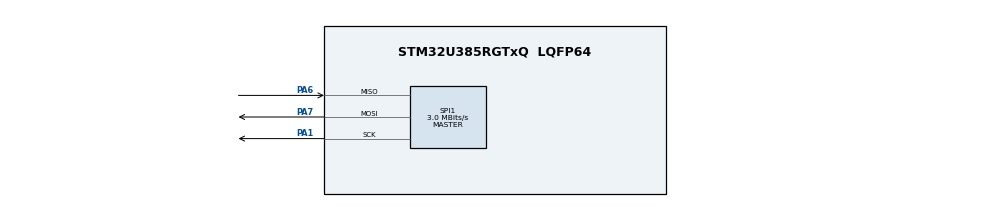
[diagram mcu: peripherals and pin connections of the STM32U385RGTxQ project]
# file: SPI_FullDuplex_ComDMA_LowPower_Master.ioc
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CORTEX_M33_NS.userName=CORTEX_M33
GPDMA1.DATAHANDLING_GPDMACH10=ENABLE
GPDMA1.DATAHANDLING_GPDMACH11=ENABLE
GPDMA1.DESTINC_GPDMACH11=DMA_DINC_INCREMENTED
GPDMA1.DIRECTION_GPDMACH10=DMA_MEMORY_TO_PERIPH
GPDMA1.IPHANDLE_GPDMACH10-SIMPLEREQUEST_GPDMACH10=__NULL
GPDMA1.IPHANDLE_GPDMACH11-SIMPLEREQUEST_GPDMACH11=__NULL
GPDMA1.REQUEST_GPDMACH10=GPDMA1_REQUEST_SPI1_TX
GPDMA1.REQUEST_GPDMACH11=GPDMA1_REQUEST_SPI1_RX
GPDMA1.SRCINC_GPDMACH10=DMA_SINC_INCREMENTED
Mcu.Family=STM32U3
Mcu.Name=STM32U385RGTxQ
Mcu.Package=LQFP64
NVIC.GPDMA1_Channel10_IRQn=true\:0\:0\:false\:false\:true\:false\:true\:true
NVIC.GPDMA1_Channel11_IRQn=true\:0\:0\:false\:false\:true\:false\:true\:true
NVIC.PriorityGroup=NVIC_PRIORITYGROUP_4
NVIC.SPI1_IRQn=true\:0\:0\:false\:false\:true\:false\:true\:true
PA1.GPIO_Speed=GPIO_SPEED_FREQ_HIGH
PA1.Mode=Full_Duplex_Master
PA1.Signal=SPI1_SCK
PA6.GPIO_Speed=GPIO_SPEED_FREQ_HIGH
PA6.Mode=Full_Duplex_Master
PA6.Signal=SPI1_MISO
PA7.GPIO_Speed=GPIO_SPEED_FREQ_HIGH
PA7.Mode=Full_Duplex_Master
PA7.Signal=SPI1_MOSI
PC14-OSC32_IN\ (PC14).Mode=LSE-External-Oscillator
PC14-OSC32_IN\ (PC14).Signal=RCC_OSC32_IN
PC15-OSC32_OUT\ (PC15).Mode=LSE-External-Oscillator
PC15-OSC32_OUT\ (PC15).Signal=RCC_OSC32_OUT
ProjectManager.HeapSize=0x200
ProjectManager.StackSize=0x400
ProjectManager.TargetToolchain=EWARM V9.20
RCC.ADCFreq_Value=24000000
RCC.AHBFreq_Value=24000000
RCC.APB1Freq_Value=24000000
RCC.APB1TimFreq_Value=24000000
RCC.APB2Freq_Value=24000000
RCC.APB2TimFreq_Value=24000000
RCC.APB3Freq_Value=24000000
RCC.CortexFreq_Value=3000000
RCC.HCLKFreq_Value=24000000
RCC.HSE_VALUE=16000000
RCC.HSI48_VALUE=48000000
RCC.HSI_VALUE=16000000
RCC.LSIDIV_VALUE=32000
RCC.MSIKSource=RCC_MSI_RC1
RCC.MSISDIV=RCC_MSI_DIV1
RCC.MSISSource=RCC_MSI_RC1
RCC.RTCClockSelection=RCC_RTCCLKSOURCE_LSE
RCC.SPI1CLockSelection=RCC_SPI1CLKSOURCE_MSIK
RCC.SYSCLKFreq_VALUE=24000000
RCC.USBFreq_Value=24000000
RTC.WakeUpCounter-WakeUp=10240
SPI1.BaudRatePrescaler=SPI_BAUDRATEPRESCALER_8
SPI1.CalculateBaudRate=3.0 MBits/s
SPI1.DataSize=SPI_DATASIZE_8BIT
SPI1.Direction=SPI_DIRECTION_2LINES
SPI1.Mode=SPI_MODE_MASTER
SPI1.TriggerSelection=SPI_GRP1_RTC_WUT_TRG
SPI1.TriggerState=SPI_AUTO_MODE_ENABLE
SPI1.VirtualType=VM_MASTER
VP_GPDMA1_VS_GPDMACH10.Mode=SIMPLEREQUEST_GPDMACH10
VP_GPDMA1_VS_GPDMACH11.Mode=SIMPLEREQUEST_GPDMACH11
VP_ICACHE_VS_ICACHE.Mode=DirectMappedCache
VP_PWR_VS_DBSignals.Mode=DisableDeadBatterySignals
VP_PWR_VS_LPOM.Mode=PowerOptimisation
VP_PWR_VS_SECSignals.Mode=Security/Privilege
VP_RTC_VS_RTC_Activate.Mode=RTC_Enabled
VP_RTC_VS_RTC_WakeUp_intern.Mode=WakeUp
board=custom

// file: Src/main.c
/* USER CODE BEGIN Header */
/**
  ******************************************************************************
  * @file           : main.c
  * @brief          : Main program body
  ******************************************************************************
  * @attention
  *
  * Copyright (c) 2024 STMicroelectronics.
  * All rights reserved.
  *
  * This software is licensed under terms that can be found in the LICENSE file
  * in the root directory of this software component.
  * If no LICENSE file comes with this software, it is provided AS-IS.
  *
  ******************************************************************************
  */
/* USER CODE END Header */
#include "main.h"

/* USER CODE BEGIN PTD */
enum {
	TRANSFER_WAIT,
	TRANSFER_COMPLETE,
	TRANSFER_ERROR
};
/* USER CODE END PTD */

/* USER CODE BEGIN PD */
uint8_t aTxBuffer[] = "****SPI - Two Boards communication based on DMA **** SPI Message ******** SPI Message ******** SPI Message ****";

/* Buffer used for reception */
#define BUFFER_ALIGNED_SIZE (((BUFFERSIZE+31)/32)*32)
ALIGN_32BYTES(uint8_t aRxBuffer[BUFFER_ALIGNED_SIZE]);

/* transfer state */
__IO uint32_t wTransferState = TRANSFER_WAIT;
/* USER CODE END PD */

RTC_HandleTypeDef hrtc;

SPI_HandleTypeDef hspi1;
DMA_HandleTypeDef handle_GPDMA1_Channel11;
DMA_HandleTypeDef handle_GPDMA1_Channel10;

void SystemClock_Config(void);
static void MX_GPIO_Init(void);
static void MX_GPDMA1_Init(void);
static void MX_SPI1_Init(void);
static void MX_ICACHE_Init(void);
static void MX_RTC_Init(void);
/* USER CODE BEGIN PFP */
static uint16_t Buffercmp(uint8_t *pBuffer1, uint8_t *pBuffer2, uint16_t BufferLength);
/* USER CODE END PFP */

int main(void)
{

  /* USER CODE BEGIN 1 */
  /* STM32U3xx HAL library initialization:
       - Configure the Flash prefetch
       - Configure the Systick to generate an interrupt each 1 msec
       - Set NVIC Group Priority to 3
       - Low Level Initialization
     */
  /* USER CODE END 1 */

  /* MCU Configuration--------------------------------------------------------*/

  /* Reset of all peripherals, Initializes the Flash interface and the Systick. */
  HAL_Init();

  /* Configure the system clock */
  SystemClock_Config();

  /* USER CODE BEGIN SysInit */
  /* Configure LED2 */
  BSP_LED_Init(LD2);

  /* USER CODE END SysInit */

  /* Initialize all configured peripherals */
  MX_GPIO_Init();
  MX_GPDMA1_Init();
  MX_SPI1_Init();
  MX_ICACHE_Init();
  MX_RTC_Init();
  /* USER CODE BEGIN 2 */

  __HAL_RTC_CLEAR_FLAG(hrtc, RTC_CLEAR_WUTF);

    /*##-2- Start the Full Duplex Communication process ########################*/
  /* While the SPI in TransmitReceive process, user can transmit data through
     "aTxBuffer" buffer & receive data through "aRxBuffer" */
  if(HAL_SPI_TransmitReceive_DMA(&hspi1, (uint8_t*)aTxBuffer, (uint8_t *)aRxBuffer, BUFFERSIZE) != HAL_OK)
  {
    /* Transfer error in transmission process */
    Error_Handler();
  }

  /* Disable debug to avoid some buses to stay awake */
  HAL_DBGMCU_DisableDBGStopMode();

  /* Suspend Tick increment */
  HAL_SuspendTick();

  /* Enter in low power mode(STOP1) and wait for the SPI end of transfer interrupt to be awoken.
    The DMA transfer is triggered by the RTC timer, the MCU is in low power mode during the RTC
    count down and during the DMA transfer */
  HAL_PWR_EnterSTOPMode(PWR_LOWPOWERMODE_STOP1, PWR_STOPENTRY_WFI);

  /* Resume Tick increment */
  HAL_ResumeTick();

  /*##-3- Wait for the end of the transfer ###################################*/
  /*  Before starting a new communication transfer, you must wait the callback call
      to get the transfer complete confirmation or an error detection. */
  while (wTransferState == TRANSFER_WAIT)
  {
  }

  switch(wTransferState)
  {
    case TRANSFER_COMPLETE :
      /*##-4- Compare the sent and received buffers ##############################*/
      if(Buffercmp((uint8_t*)aTxBuffer, (uint8_t*)aRxBuffer, BUFFERSIZE))
      {
        /* Processing Error */
        Error_Handler();
      }
    break;
    default :
      Error_Handler();
    break;
  }
  /* USER CODE END 2 */

  /* Infinite loop */
  while (1)
  {

  }
}

void SystemClock_Config(void)
{
  RCC_OscInitTypeDef RCC_OscInitStruct = {0};
  RCC_ClkInitTypeDef RCC_ClkInitStruct = {0};

  /** Configure the System Power Supply
  */
  if (HAL_PWREx_ConfigSupply(PWR_SMPS_SUPPLY) != HAL_OK)
  {
    Error_Handler();
  }

  /** Configure the main internal regulator output voltage
  */
  if (HAL_PWREx_ControlVoltageScaling(PWR_REGULATOR_VOLTAGE_SCALE2) != HAL_OK)
  {
    Error_Handler();
  }

  /** Configure LSE Drive Capability
  */
  HAL_PWR_EnableBkUpAccess();
  __HAL_RCC_LSEDRIVE_CONFIG(RCC_LSEDRIVE_LOW);

  /** Initializes the CPU, AHB and APB buses clocks
  */
  RCC_OscInitStruct.OscillatorType = RCC_OSCILLATORTYPE_LSE|RCC_OSCILLATORTYPE_MSIS
                              |RCC_OSCILLATORTYPE_MSIK;
  RCC_OscInitStruct.LSEState = RCC_LSE_ON;
  RCC_OscInitStruct.MSISState = RCC_MSI_ON;
  RCC_OscInitStruct.MSISSource = RCC_MSI_RC1;
  RCC_OscInitStruct.MSISDiv = RCC_MSI_DIV1;
  RCC_OscInitStruct.MSIKState = RCC_MSI_ON;
  RCC_OscInitStruct.MSIKSource = RCC_MSI_RC1;
  RCC_OscInitStruct.MSIKDiv = RCC_MSI_DIV1;

  if (HAL_RCC_OscConfig(&RCC_OscInitStruct) != HAL_OK)
  {
    Error_Handler();
  }

  /** Initializes the CPU, AHB and APB buses clocks
  */
  RCC_ClkInitStruct.ClockType = RCC_CLOCKTYPE_HCLK|RCC_CLOCKTYPE_SYSCLK
                              |RCC_CLOCKTYPE_PCLK1|RCC_CLOCKTYPE_PCLK2
                              |RCC_CLOCKTYPE_PCLK3;
  RCC_ClkInitStruct.SYSCLKSource = RCC_SYSCLKSOURCE_MSIS;
  RCC_ClkInitStruct.AHBCLKDivider = RCC_SYSCLK_DIV1;
  RCC_ClkInitStruct.APB1CLKDivider = RCC_HCLK_DIV1;
  RCC_ClkInitStruct.APB2CLKDivider = RCC_HCLK_DIV1;
  RCC_ClkInitStruct.APB3CLKDivider = RCC_HCLK_DIV1;

  if (HAL_RCC_ClockConfig(&RCC_ClkInitStruct, FLASH_LATENCY_1) != HAL_OK)
  {
    Error_Handler();
  }
}

static void MX_GPDMA1_Init(void)
{

  /* Peripheral clock enable */
  __HAL_RCC_GPDMA1_CLK_ENABLE();

  /* GPDMA1 interrupt Init */
    HAL_NVIC_SetPriority(GPDMA1_Channel10_IRQn, 0, 0);
    HAL_NVIC_EnableIRQ(GPDMA1_Channel10_IRQn);
    HAL_NVIC_SetPriority(GPDMA1_Channel11_IRQn, 0, 0);
    HAL_NVIC_EnableIRQ(GPDMA1_Channel11_IRQn);

}

static void MX_ICACHE_Init(void)
{

  /** Enable instruction cache in 1-way (direct mapped cache)
  */
  if (HAL_ICACHE_ConfigAssociativityMode(ICACHE_1WAY) != HAL_OK)
  {
    Error_Handler();
  }
  if (HAL_ICACHE_Enable() != HAL_OK)
  {
    Error_Handler();
  }

}

static void MX_RTC_Init(void)
{

  RTC_PrivilegeStateTypeDef privilegeState = {0};

  /** Initialize RTC Only
  */
  hrtc.Instance = RTC;
  hrtc.Init.HourFormat = RTC_HOURFORMAT_24;
  hrtc.Init.AsynchPrediv = 127;
  hrtc.Init.SynchPrediv = 255;
  hrtc.Init.OutPut = RTC_OUTPUT_DISABLE;
  hrtc.Init.OutPutRemap = RTC_OUTPUT_REMAP_NONE;
  hrtc.Init.OutPutPolarity = RTC_OUTPUT_POLARITY_HIGH;
  hrtc.Init.OutPutType = RTC_OUTPUT_TYPE_OPENDRAIN;
  hrtc.Init.OutPutPullUp = RTC_OUTPUT_PULLUP_NONE;
  hrtc.Init.BinMode = RTC_BINARY_NONE;
  if (HAL_RTC_Init(&hrtc) != HAL_OK)
  {
    Error_Handler();
  }
  privilegeState.rtcPrivilegeFull = RTC_PRIVILEGE_FULL_NO;
  privilegeState.backupRegisterPrivZone = RTC_PRIVILEGE_BKUP_ZONE_NONE;
  privilegeState.backupRegisterStartZone2 = RTC_BKP_DR0;
  privilegeState.backupRegisterStartZone3 = RTC_BKP_DR0;
  if (HAL_RTCEx_PrivilegeModeSet(&hrtc, &privilegeState) != HAL_OK)
  {
    Error_Handler();
  }

  /** Enable the WakeUp
  */
  if (HAL_RTCEx_SetWakeUpTimer(&hrtc, 10240, RTC_WAKEUPCLOCK_RTCCLK_DIV16) != HAL_OK)
  {
    Error_Handler();
  }
  /* USER CODE BEGIN RTC_Init 2 */
  /* Wake up time is defined by HAL_RTCEx_SetWakeUpTimer_IT() API
     Wake up time = Wake up initial counter / (RTC input frequency / RTC wake up clock divider)
                  = 10240 / (32768 / 16)
                  = 5 seconds */
  /* USER CODE END RTC_Init 2 */

}

static void MX_SPI1_Init(void)
{

  SPI_AutonomousModeConfTypeDef HAL_SPI_AutonomousMode_Cfg_Struct = {0};

  /* SPI1 parameter configuration*/
  hspi1.Instance = SPI1;
  hspi1.Init.Mode = SPI_MODE_MASTER;
  hspi1.Init.Direction = SPI_DIRECTION_2LINES;
  hspi1.Init.DataSize = SPI_DATASIZE_8BIT;
  hspi1.Init.CLKPolarity = SPI_POLARITY_LOW;
  hspi1.Init.CLKPhase = SPI_PHASE_1EDGE;
  hspi1.Init.NSS = SPI_NSS_SOFT;
  hspi1.Init.BaudRatePrescaler = SPI_BAUDRATEPRESCALER_8;
  hspi1.Init.FirstBit = SPI_FIRSTBIT_MSB;
  hspi1.Init.TIMode = SPI_TIMODE_DISABLE;
  hspi1.Init.CRCCalculation = SPI_CRCCALCULATION_DISABLE;
  hspi1.Init.CRCPolynomial = 0x7;
  hspi1.Init.NSSPMode = SPI_NSS_PULSE_ENABLE;
  hspi1.Init.NSSPolarity = SPI_NSS_POLARITY_LOW;
  hspi1.Init.FifoThreshold = SPI_FIFO_THRESHOLD_01DATA;
  hspi1.Init.MasterSSIdleness = SPI_MASTER_SS_IDLENESS_00CYCLE;
  hspi1.Init.MasterInterDataIdleness = SPI_MASTER_INTERDATA_IDLENESS_00CYCLE;
  hspi1.Init.MasterReceiverAutoSusp = SPI_MASTER_RX_AUTOSUSP_DISABLE;
  hspi1.Init.MasterKeepIOState = SPI_MASTER_KEEP_IO_STATE_DISABLE;
  hspi1.Init.IOSwap = SPI_IO_SWAP_DISABLE;
  hspi1.Init.ReadyMasterManagement = SPI_RDY_MASTER_MANAGEMENT_INTERNALLY;
  hspi1.Init.ReadyPolarity = SPI_RDY_POLARITY_HIGH;
  if (HAL_SPI_Init(&hspi1) != HAL_OK)
  {
    Error_Handler();
  }
  HAL_SPI_AutonomousMode_Cfg_Struct.TriggerState = SPI_AUTO_MODE_ENABLE;
  HAL_SPI_AutonomousMode_Cfg_Struct.TriggerSelection = SPI_GRP1_RTC_WUT_TRG;
  HAL_SPI_AutonomousMode_Cfg_Struct.TriggerPolarity = SPI_TRIG_POLARITY_RISING;
  if (HAL_SPIEx_SetConfigAutonomousMode(&hspi1, &HAL_SPI_AutonomousMode_Cfg_Struct) != HAL_OK)
  {
    Error_Handler();
  }

}

static void MX_GPIO_Init(void)
{

  /* GPIO Ports Clock Enable */
  __HAL_RCC_GPIOA_CLK_ENABLE();

}

/* USER CODE BEGIN 4 */
/**
  * @brief  TxRx Transfer completed callback.
  * @param  hspi: SPI handle
  * @note   This example shows a simple way to report end of DMA TxRx transfer, and
  *         you can add your own implementation.
  * @retval None
  */
void HAL_SPI_TxRxCpltCallback(SPI_HandleTypeDef *hspi)
{
  /* Turn LED2 on: Transfer in transmission/reception process is complete */
  BSP_LED_On(LD2);
  wTransferState = TRANSFER_COMPLETE;

}

/**
  * @brief  SPI error callbacks.
  * @param  hspi: SPI handle
  * @note   This example shows a simple way to report transfer error, and you can
  *         add your own implementation.
  * @retval None
  */
void HAL_SPI_ErrorCallback(SPI_HandleTypeDef *hspi)
{
  wTransferState = TRANSFER_ERROR;
}

/**
  * @brief  Compares two buffers.
  * @param  pBuffer1, pBuffer2: buffers to be compared.
  * @param  BufferLength: buffer's length
  * @retval 0  : pBuffer1 identical to pBuffer2
  *         >0 : pBuffer1 differs from pBuffer2
  */
static uint16_t Buffercmp(uint8_t *pBuffer1, uint8_t *pBuffer2, uint16_t BufferLength)
{
  while (BufferLength--)
  {
    if((*pBuffer1) != *pBuffer2)
    {
      return BufferLength;
    }
    pBuffer1++;
    pBuffer2++;
  }

  return 0;
}

/* USER CODE END 4 */

void Error_Handler(void)
{
  /* USER CODE BEGIN Error_Handler_Debug */
  /* User can add his own implementation to report the HAL error return state */
  /* Turn LED2 off */
  BSP_LED_Off(LD2);
  /* Toggle LED2 for error */
  while(1)
  {
    BSP_LED_Toggle(LD2);
    HAL_Delay(1000);
  }
  /* USER CODE END Error_Handler_Debug */
}
